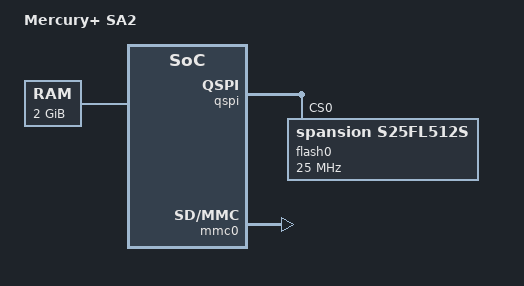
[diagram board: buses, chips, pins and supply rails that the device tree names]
#include "socfpga_cyclone5.dtsi"

/ {
	model = "Mercury+ SA2";
	compatible = "altr,socfpga-cyclone5", "altr,socfpga";

	chosen {
		bootargs = "earlyprintk";
		stdout-path = "serial0:115200n8";
	};

	memory@0 {
		name = "memory";
		device_type = "memory";
		reg = <0x0 0x80000000>; /* 2GB */
	};

	soc {
		clkmgr@ffd04000 {
			clocks {
				osc1 {
					clock-frequency = <50000000>;
				};
			};
		};
	};
};

&qspi {
	status = "okay";

	flash0: s25fl512s@0 {
		u-boot,dm-pre-reloc;
		#address-cells = <1>;
		#size-cells = <1>;
		compatible = "spansion,s25fl512s", "jedec,spi-nor";
		reg = <0>;
		spi-max-frequency = <25000000>;

		page-size = <256>;
		block-size = <16>; /* 2^16, 64KB */
		cdns,page-size = <256>;
		cdns,block-size = <16>;
		cdns,read-delay = <4>;
		cdns,tshsl-ns = <50>;
		cdns,tsd2d-ns = <50>;
		cdns,tchsh-ns = <4>;
		cdns,tslch-ns = <4>;
	};
};

&mmc0 {
	status = "okay";
};

